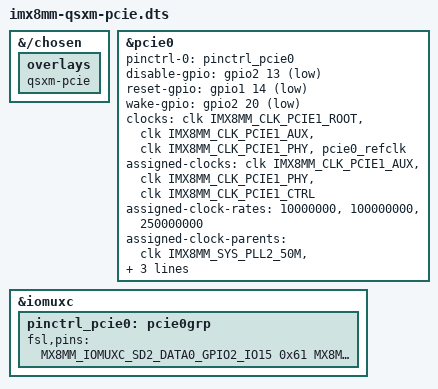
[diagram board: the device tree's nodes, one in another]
// SPDX-License-Identifier: (GPL-2.0 OR MIT)
/*
 * Copyright 2022 Lothar Waßmann <LW@KARO-electronics.de>
 *
 */

/dts-v1/;

/plugin/;

#include <dt-bindings/clock/imx8mm-clock.h>
#include <dt-bindings/gpio/gpio.h>
#include "imx8mm-pinfunc.h"
#include "overlays/imx8m-karo-pcie.dtsi"

&{/chosen} {
	overlays {
		qsxm-pcie;
	};
};

&pcie0 {
	pinctrl-names = "default";
	pinctrl-0 = <&pinctrl_pcie0>;
	disable-gpio = <&gpio2 13 GPIO_ACTIVE_LOW>;
	reset-gpio = <&gpio1 14 GPIO_ACTIVE_LOW>;
	wake-gpio = <&gpio2 20 GPIO_ACTIVE_LOW>;
	clocks = <&clk IMX8MM_CLK_PCIE1_ROOT>,
		 <&clk IMX8MM_CLK_PCIE1_AUX>,
		 <&clk IMX8MM_CLK_PCIE1_PHY>,
		 <&pcie0_refclk>;
	clock-names = "pcie", "pcie_aux", "pcie_phy", "pcie_bus";
	assigned-clocks = <&clk IMX8MM_CLK_PCIE1_AUX>,
			  <&clk IMX8MM_CLK_PCIE1_PHY>,
			  <&clk IMX8MM_CLK_PCIE1_CTRL>;
	assigned-clock-rates = <10000000>, <100000000>, <250000000>;
	assigned-clock-parents = <&clk IMX8MM_SYS_PLL2_50M>,
				 <&clk IMX8MM_SYS_PLL2_100M>,
				 <&clk IMX8MM_SYS_PLL2_250M>;
	ext_osc = <1>;
};

&iomuxc {
	pinctrl_pcie0: pcie0grp {
		fsl,pins = <
			MX8MM_IOMUXC_SD2_DATA0_GPIO2_IO15	0x61 /* open drain, pull up */
			MX8MM_IOMUXC_SD2_CLK_GPIO2_IO13		0x41
			MX8MM_IOMUXC_GPIO1_IO14_GPIO1_IO14	0x41
			MX8MM_IOMUXC_SD2_WP_GPIO2_IO20		0x41
		>;
	};
};
